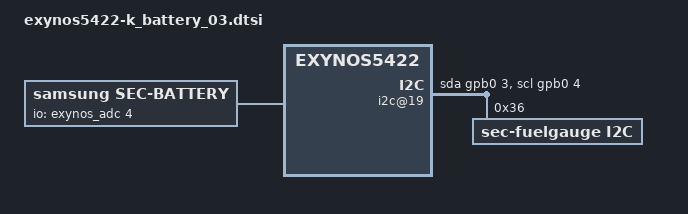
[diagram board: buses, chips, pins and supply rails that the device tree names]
/*
 * SAMSUNG UNIVERSAL5430 board device tree source
 *
 * Copyright (c) 2013 Samsung Electronics Co., Ltd.
 *		http://www.samsung.com
 *
 * This program is free software; you can redistribute it and/or modify
 * it under the terms of the GNU General Public License version 2 as
 * published by the Free Software Foundation.
*/

/ {
        i2c@19{
                compatible = "i2c-gpio";
                gpios = <&gpb0 3 0 /* sda */
                         &gpb0 4 0 /* scl */
                        >;
                i2c-gpio,delay-us = <2>;
                #address-cells = <1>;
                #size-cells = <0>;
		status = "okay";
		sec-fuelgauge@36 {
			compatible = "sec-fuelgauge,i2c";
			reg = <0x36>;
			pinctrl-names = "default";
			pinctrl-0 = <&fuel_irq>;
			fuelgauge,fuel_int = <&gpx1 5 0>;
			fuelgauge,fuel_alert_soc = <2>;
			fuelgauge,capacity_max = <990>;
			fuelgauge,capacity_max_margin = <30>;
			fuelgauge,capacity_min = <0>;
			fuelgauge,capacity_calculation_type = <28>;
			fuelgaguge,repeated_fuelalert;
			fuelgauge,rcomp0 = <0x5D>;
			fuelgauge,rcomp_charging = <0x5D>;
			fuelgauge,temp_cohot = <(-175)>;
			fuelgauge,temp_cocold = <(-5825)>;
			fuelgauge,is_using_model_data;
			fuelgauge,type_str = "SDI";
		};
	};

	battery {
		status = "okay";
		compatible = "samsung,sec-battery";
		battery,vendor = "SDI SDI";
		battery,charger_name = "sec-charger";
		battery,fuelgauge_name = "sec-fuelgauge";
		battery,technology = <2>; /* POWER_SUPPLY_TECHNOLOGY_LION */

		battery,chip_vendor = "LSI";
		battery,temp_adc_type = <1>; /* SEC_BATTERY_ADC_TYPE_AP */

		battery,polling_time = <10 30 30 30 3600>;

		battery,temp_table_adc = <276 326 383 455 530 629 740 787 866 1013
				         1181 1361 1564 1792 2024 2263 2493 2728 2948 3011
					 3135 3208 3313 3465 3588 3698 3779>;
		battery,temp_table_data = <900 850 800 750 700 650 600 580 550 500
					   450 400 350 300 250 200 150 100 50 30
					   0 (-20) (-50) (-100) (-150) (-200) (-250)>;

		battery,input_current_limit = <1800 0 0 1800 460 900 1000 460 1000 0 760 1900 0 0 0 400 700 1300 300 1000 1600>;
		battery,fast_charging_current = <2100 0 0 2100 460 1200 1000 460 1200 0 900 1600 0 0 0 400 700 1300 300 1000 1900>;
		battery,full_check_current_1st = <200 0 0 200 200 200 200 200 200 0 200 200 0 0 0 200 200 200 200 200 200>;
		battery,full_check_current_2nd = <125 0 0 125 125 125 125 125 125 0 125 125 0 0 0 125 125 125 125 125 125>;

		battery,adc_check_count = <5>;

		battery,cable_check_type = <4>; /* SEC_BATTERY_CABLE_CHECK_PSY */
		battery,cable_source_type = <1>; /* SEC_BATTERY_CABLE_SOURCE_EXTERNAL */
		battery,event_waiting_time = <600>;
		battery,polling_type = <1>; /* SEC_BATTERY_MONITOR_ALARM */
		battery,monitor_initial_count = <0>;

		battery,battery_check_type = <5>; /* SEC_BATTERY_CHECK_CHARGER */
		battery,check_count = <0>;
		battery,check_adc_max = <1440>;
		battery,check_adc_min = <0>;

		battery,ovp_uvlo_check_type = <3>; /* SEC_BATTERY_OVP_UVLO_CHGPOLLING */

		battery,thermal_source = <2>; /* SEC_BATTERY_THERMAL_SOURCE_ADC */

		battery,temp_check_type = <2>; /* _BATTERY_TEMP_CHECK_TEMP */
		battery,temp_check_count = <1>;
		battery,temp_highlimit_threshold_event = <800>;
		battery,temp_highlimit_recovery_event = <750>;
		battery,temp_high_threshold_event = <580>;
		battery,temp_high_recovery_event = <530>;
		battery,temp_low_threshold_event = <(-30)>;
		battery,temp_low_recovery_event = <0>;
		battery,temp_highlimit_threshold_normal = <800>;
		battery,temp_highlimit_recovery_normal = <750>;
		battery,temp_high_threshold_normal = <580>;
		battery,temp_high_recovery_normal = <530>;
		battery,temp_low_threshold_normal = <(-50)>;
		battery,temp_low_recovery_normal = <0>;
		battery,temp_highlimit_threshold_lpm = <800>;
		battery,temp_highlimit_recovery_lpm = <750>;
		battery,temp_high_threshold_lpm = <580>;
		battery,temp_high_recovery_lpm = <530>;
		battery,temp_low_threshold_lpm = <(-50)>;
		battery,temp_low_recovery_lpm = <0>;
		battery,full_check_type = <7>; /* SEC_BATTERY_FULLCHARGED_CHGPSY */
		battery,full_check_type_2nd = <7>; /* SEC_BATTERY_FULLCHARGED_CHGPSY */
		battery,full_check_count = <1>;
		battery,chg_gpio_full_check = <0>;
		battery,chg_polarity_full_check = <1>;

		/* SEC_BATTERY_FULL_CONDITION_SOC |
		   SEC_BATTERY_FULL_CONDITION_NOTIMEFULL |
		   SEC_BATTERY_FULL_CONDITION_VCELL */
		battery,full_condition_type = <13>;
		battery,full_condition_soc = <97>;
		battery,full_condition_vcell = <4350>;

		battery,recharge_check_count = <2>;
		battery,recharge_condition_type = <4>; /* SEC_BATTERY_RECHARGE_CONDITION_VCELL */
		battery,recharge_condition_soc = <98>;
		battery,recharge_condition_vcell = <4350>;

		battery,charging_total_time = <21600>;
		battery,recharging_total_time = <5400>;
		battery,charging_reset_time = <0>;

		io-channels = <&exynos_adc 4>;
		io-channel-names = "adc-temp";
		#io-channel-cells = <1>;
		io-channel-ranges;
	};

	charger {
		status = "disable";
                /* Charger */
                battery,charger_name = "sec-charger";
                battery,chg_gpio_en = <0>;
                battery,chg_polarity_en = <0>;
                battery,chg_gpio_status = <0>;
                battery,chg_polarity_status = <0>;
                battery,chg_float_voltage = <4400>;
	};
};
